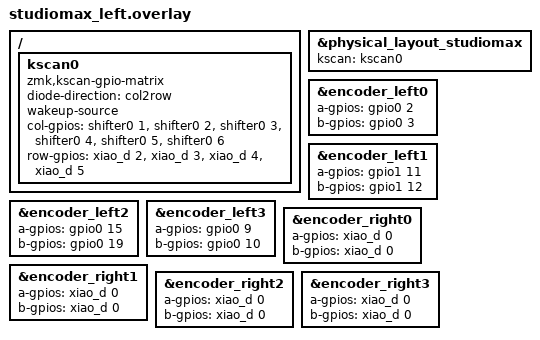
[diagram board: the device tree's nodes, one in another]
#include "studiomax.dtsi"

/ {
    kscan0: kscan0 {
        compatible = "zmk,kscan-gpio-matrix";
                diode-direction = "col2row";
        wakeup-source;

        col-gpios
            = <&shifter0 1 GPIO_ACTIVE_HIGH>
            , <&shifter0 2 GPIO_ACTIVE_HIGH>
            , <&shifter0 3 GPIO_ACTIVE_HIGH>
            , <&shifter0 4 GPIO_ACTIVE_HIGH>
            , <&shifter0 5 GPIO_ACTIVE_HIGH>
            , <&shifter0 6 GPIO_ACTIVE_HIGH>
            ;

        row-gpios
            = <&xiao_d 2 (GPIO_ACTIVE_HIGH | GPIO_PULL_DOWN)>
            , <&xiao_d 3 (GPIO_ACTIVE_HIGH | GPIO_PULL_DOWN)>
            , <&xiao_d 4 (GPIO_ACTIVE_HIGH | GPIO_PULL_DOWN)>
            , <&xiao_d 5 (GPIO_ACTIVE_HIGH | GPIO_PULL_DOWN)>
            ;
    };
};

&physical_layout_studiomax {
    kscan = <&kscan0>;
};

&encoder_left0 {
    a-gpios = <&gpio0 2 (GPIO_ACTIVE_HIGH | GPIO_PULL_UP)>;
    b-gpios = <&gpio0 3 (GPIO_ACTIVE_HIGH | GPIO_PULL_UP)>;
    status = "okay";
};
&encoder_left1 {
    a-gpios = <&gpio1 11 (GPIO_ACTIVE_HIGH | GPIO_PULL_UP)>;
    b-gpios = <&gpio1 12 (GPIO_ACTIVE_HIGH | GPIO_PULL_UP)>;
    status = "okay";
};
&encoder_left2 {
    a-gpios = <&gpio0 15 (GPIO_ACTIVE_HIGH | GPIO_PULL_UP)>;
    b-gpios = <&gpio0 19 (GPIO_ACTIVE_HIGH | GPIO_PULL_UP)>;    
    status = "okay";
};
&encoder_left3 {
    a-gpios = <&gpio0 9 (GPIO_ACTIVE_HIGH | GPIO_PULL_UP)>;
    b-gpios = <&gpio0 10 (GPIO_ACTIVE_HIGH | GPIO_PULL_UP)>;
    status = "okay";
};

// Assigning dummy pins to other part's encoders
// just to satisfy the devicetree requirements.
// No code will be compiled for these disabled encoders.
&encoder_right0 {
    a-gpios = <&xiao_d 0 (GPIO_ACTIVE_HIGH | GPIO_PULL_UP)>;
    b-gpios = <&xiao_d 0 (GPIO_ACTIVE_HIGH | GPIO_PULL_UP)>;
};
&encoder_right1 {
    a-gpios = <&xiao_d 0 (GPIO_ACTIVE_HIGH | GPIO_PULL_UP)>;
    b-gpios = <&xiao_d 0 (GPIO_ACTIVE_HIGH | GPIO_PULL_UP)>;
};
&encoder_right2 {
    a-gpios = <&xiao_d 0 (GPIO_ACTIVE_HIGH | GPIO_PULL_UP)>;
    b-gpios = <&xiao_d 0 (GPIO_ACTIVE_HIGH | GPIO_PULL_UP)>;
};
&encoder_right3 {
    a-gpios = <&xiao_d 0 (GPIO_ACTIVE_HIGH | GPIO_PULL_UP)>;
    b-gpios = <&xiao_d 0 (GPIO_ACTIVE_HIGH | GPIO_PULL_UP)>;
};

